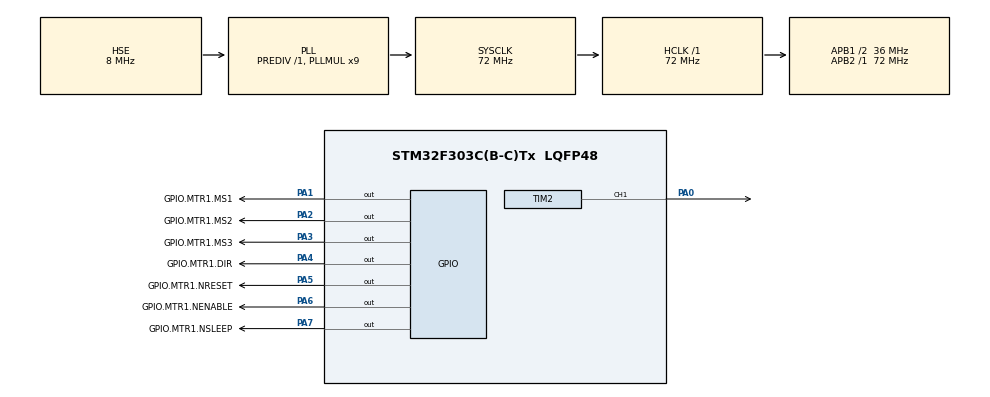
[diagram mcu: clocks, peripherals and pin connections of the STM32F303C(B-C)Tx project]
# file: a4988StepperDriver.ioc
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FREERTOS.Tasks01=defaultTask,24,128,StartDefaultTask,Default,NULL,Dynamic,NULL,NULL
FREERTOS.configUSE_NEWLIB_REENTRANT=1
Mcu.Family=STM32F3
Mcu.Name=STM32F303C(B-C)Tx
Mcu.Package=LQFP48
NVIC.PriorityGroup=NVIC_PRIORITYGROUP_4
NVIC.TIM6_DAC_IRQn=true\:15\:0\:false\:false\:true\:false\:false\:true\:true
NVIC.TimeBase=TIM6_DAC_IRQn
NVIC.TimeBaseIP=TIM6
PA0.Signal=S_TIM2_CH1_ETR
PA1.GPIO_Label=GPIO.MTR1.MS1
PA1.Signal=GPIO_Output
PA13.Mode=Serial_Wire
PA13.Signal=SYS_JTMS-SWDIO
PA14.Mode=Serial_Wire
PA14.Signal=SYS_JTCK-SWCLK
PA2.GPIO_Label=GPIO.MTR1.MS2
PA2.Signal=GPIO_Output
PA3.GPIO_Label=GPIO.MTR1.MS3
PA3.Signal=GPIO_Output
PA4.GPIO_Label=GPIO.MTR1.DIR
PA4.Signal=GPIO_Output
PA5.GPIO_Label=GPIO.MTR1.NRESET
PA5.Signal=GPIO_Output
PA6.GPIO_Label=GPIO.MTR1.NENABLE
PA6.Signal=GPIO_Output
PA7.GPIO_Label=GPIO.MTR1.NSLEEP
PA7.Signal=GPIO_Output
PF0-OSC_IN.Mode=HSE-External-Oscillator
PF0-OSC_IN.Signal=RCC_OSC_IN
PF1-OSC_OUT.Mode=HSE-External-Oscillator
PF1-OSC_OUT.Signal=RCC_OSC_OUT
ProjectManager.HeapSize=0x200
ProjectManager.StackSize=0x400
ProjectManager.TargetToolchain=STM32CubeIDE
RCC.AHBFreq_Value=72000000
RCC.APB1CLKDivider=RCC_HCLK_DIV2
RCC.APB1Freq_Value=36000000
RCC.APB1TimFreq_Value=72000000
RCC.APB2Freq_Value=72000000
RCC.APB2TimFreq_Value=72000000
RCC.CortexFreq_Value=72000000
RCC.HCLKFreq_Value=72000000
RCC.HSE_VALUE=8000000
RCC.HSI_VALUE=8000000
RCC.LSE_VALUE=32768
RCC.PLLMUL=RCC_PLL_MUL9
RCC.PLLSourceVirtual=RCC_PLLSOURCE_HSE
RCC.SYSCLKFreq_VALUE=72000000
RCC.SYSCLKSourceVirtual=RCC_SYSCLKSOURCE_PLLCLK
RCC.USBFreq_Value=72000000
SH.S_TIM2_CH1_ETR.0=TIM2_CH1,PWM Generation1 CH1
TIM2.AutoReloadPreload=TIM_AUTORELOAD_PRELOAD_ENABLE
TIM2.Channel-PWM\ Generation1\ CH1=TIM_CHANNEL_1
TIM2.Period=2-1
TIM2.Prescaler=72-1
TIM2.Pulse-PWM\ Generation1\ CH1=1-1
VP_FREERTOS_VS_CMSIS_V2.Mode=CMSIS_V2
VP_SYS_VS_tim6.Mode=TIM6
board=custom

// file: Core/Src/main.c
/* USER CODE BEGIN Header */
/**
  ******************************************************************************
  * @file           : main.c
  * @brief          : Main program body
  ******************************************************************************
  * @attention
  *
  * Copyright (c) 2024 STMicroelectronics.
  * All rights reserved.
  *
  * This software is licensed under terms that can be found in the LICENSE file
  * in the root directory of this software component.
  * If no LICENSE file comes with this software, it is provided AS-IS.
  *
  ******************************************************************************
  */
/* USER CODE END Header */
#include "main.h"
#include "cmsis_os.h"

/* USER CODE BEGIN Includes */
#include "stepperDemo.h"
#include "a4988.h"

/* USER CODE END Includes */

/* Definitions for defaultTask */
osThreadId_t defaultTaskHandle;
const osThreadAttr_t defaultTask_attributes = {
  .name = "defaultTask",
  .stack_size = 128 * 4,
  .priority = (osPriority_t) osPriorityNormal,
};

void SystemClock_Config(void);
static void MX_GPIO_Init(void);
static void MX_TIM2_Init(void);
void StartDefaultTask(void *argument);

int main(void)
{

  /* MCU Configuration--------------------------------------------------------*/

  /* Reset of all peripherals, Initializes the Flash interface and the Systick. */
  HAL_Init();

  /* Configure the system clock */
  SystemClock_Config();

  /* Initialize all configured peripherals */
  MX_GPIO_Init();
  MX_TIM2_Init();

  /* Init scheduler */
  osKernelInitialize();

  /* Create the thread(s) */
  /* creation of defaultTask */
  defaultTaskHandle = osThreadNew(StartDefaultTask, NULL, &defaultTask_attributes);

  /* Start scheduler */
  osKernelStart();

  /* We should never get here as control is now taken by the scheduler */
  /* Infinite loop */
  while (1)
  {

  }
}

void SystemClock_Config(void)
{
  RCC_OscInitTypeDef RCC_OscInitStruct = {0};
  RCC_ClkInitTypeDef RCC_ClkInitStruct = {0};

  /** Initializes the RCC Oscillators according to the specified parameters
  * in the RCC_OscInitTypeDef structure.
  */
  RCC_OscInitStruct.OscillatorType = RCC_OSCILLATORTYPE_HSE;
  RCC_OscInitStruct.HSEState = RCC_HSE_ON;
  RCC_OscInitStruct.HSEPredivValue = RCC_HSE_PREDIV_DIV1;
  RCC_OscInitStruct.HSIState = RCC_HSI_ON;
  RCC_OscInitStruct.PLL.PLLState = RCC_PLL_ON;
  RCC_OscInitStruct.PLL.PLLSource = RCC_PLLSOURCE_HSE;
  RCC_OscInitStruct.PLL.PLLMUL = RCC_PLL_MUL9;
  if (HAL_RCC_OscConfig(&RCC_OscInitStruct) != HAL_OK)
  {
    Error_Handler();
  }

  /** Initializes the CPU, AHB and APB buses clocks
  */
  RCC_ClkInitStruct.ClockType = RCC_CLOCKTYPE_HCLK|RCC_CLOCKTYPE_SYSCLK
                              |RCC_CLOCKTYPE_PCLK1|RCC_CLOCKTYPE_PCLK2;
  RCC_ClkInitStruct.SYSCLKSource = RCC_SYSCLKSOURCE_PLLCLK;
  RCC_ClkInitStruct.AHBCLKDivider = RCC_SYSCLK_DIV1;
  RCC_ClkInitStruct.APB1CLKDivider = RCC_HCLK_DIV2;
  RCC_ClkInitStruct.APB2CLKDivider = RCC_HCLK_DIV1;

  if (HAL_RCC_ClockConfig(&RCC_ClkInitStruct, FLASH_LATENCY_2) != HAL_OK)
  {
    Error_Handler();
  }
}

static void MX_TIM2_Init(void)
{

  LL_TIM_InitTypeDef TIM_InitStruct = {0};
  LL_TIM_OC_InitTypeDef TIM_OC_InitStruct = {0};

  LL_GPIO_InitTypeDef GPIO_InitStruct = {0};

  /* Peripheral clock enable */
  LL_APB1_GRP1_EnableClock(LL_APB1_GRP1_PERIPH_TIM2);

  TIM_InitStruct.Prescaler = 72-1;
  TIM_InitStruct.CounterMode = LL_TIM_COUNTERMODE_UP;
  TIM_InitStruct.Autoreload = 100-1;
  TIM_InitStruct.ClockDivision = LL_TIM_CLOCKDIVISION_DIV1;
  LL_TIM_Init(TIM2, &TIM_InitStruct);
  LL_TIM_EnableARRPreload(TIM2);
  LL_TIM_OC_EnablePreload(TIM2, LL_TIM_CHANNEL_CH1);
  TIM_OC_InitStruct.OCMode = LL_TIM_OCMODE_PWM1;
  TIM_OC_InitStruct.OCState = LL_TIM_OCSTATE_DISABLE;
  TIM_OC_InitStruct.OCNState = LL_TIM_OCSTATE_DISABLE;
  TIM_OC_InitStruct.CompareValue = 50-1;
  TIM_OC_InitStruct.OCPolarity = LL_TIM_OCPOLARITY_HIGH;
  LL_TIM_OC_Init(TIM2, LL_TIM_CHANNEL_CH1, &TIM_OC_InitStruct);
  LL_TIM_OC_DisableFast(TIM2, LL_TIM_CHANNEL_CH1);
  LL_TIM_SetTriggerOutput(TIM2, LL_TIM_TRGO_RESET);
  LL_TIM_DisableMasterSlaveMode(TIM2);
  LL_AHB1_GRP1_EnableClock(LL_AHB1_GRP1_PERIPH_GPIOA);
  /**TIM2 GPIO Configuration
  PA0   ------> TIM2_CH1
  */
  GPIO_InitStruct.Pin = LL_GPIO_PIN_0;
  GPIO_InitStruct.Mode = LL_GPIO_MODE_ALTERNATE;
  GPIO_InitStruct.Speed = LL_GPIO_SPEED_FREQ_LOW;
  GPIO_InitStruct.OutputType = LL_GPIO_OUTPUT_PUSHPULL;
  GPIO_InitStruct.Pull = LL_GPIO_PULL_NO;
  GPIO_InitStruct.Alternate = LL_GPIO_AF_1;
  LL_GPIO_Init(GPIOA, &GPIO_InitStruct);

}

static void MX_GPIO_Init(void)
{
  GPIO_InitTypeDef GPIO_InitStruct = {0};

  /* GPIO Ports Clock Enable */
  __HAL_RCC_GPIOF_CLK_ENABLE();
  __HAL_RCC_GPIOA_CLK_ENABLE();

  /*Configure GPIO pin Output Level */
  HAL_GPIO_WritePin(GPIOA, GPIO_MTR1_MS1_Pin|GPIO_MTR1_MS2_Pin|GPIO_MTR1_MS3_Pin|GPIO_MTR1_DIR_Pin
                          |GPIO_MTR1_NRESET_Pin|GPIO_MTR1_NENABLE_Pin|GPIO_MTR1_NSLEEP_Pin, GPIO_PIN_RESET);

  /*Configure GPIO pins : GPIO_MTR1_MS1_Pin GPIO_MTR1_MS2_Pin GPIO_MTR1_MS3_Pin GPIO_MTR1_DIR_Pin
                           GPIO_MTR1_NRESET_Pin GPIO_MTR1_NENABLE_Pin GPIO_MTR1_NSLEEP_Pin */
  GPIO_InitStruct.Pin = GPIO_MTR1_MS1_Pin|GPIO_MTR1_MS2_Pin|GPIO_MTR1_MS3_Pin|GPIO_MTR1_DIR_Pin
                          |GPIO_MTR1_NRESET_Pin|GPIO_MTR1_NENABLE_Pin|GPIO_MTR1_NSLEEP_Pin;
  GPIO_InitStruct.Mode = GPIO_MODE_OUTPUT_PP;
  GPIO_InitStruct.Pull = GPIO_NOPULL;
  GPIO_InitStruct.Speed = GPIO_SPEED_FREQ_LOW;
  HAL_GPIO_Init(GPIOA, &GPIO_InitStruct);

}

void StartDefaultTask(void *argument)
{
  /* USER CODE BEGIN 5 */
	STP_Startup();
	STP_SetFrequency(1000);
    osDelay(1000);
	STP_SetFrequency(5000);
    osDelay(1000);
	A4988_SET_MICROSTEP_EIGHTHSTEP();
    osDelay(1000);
	A4988_SET_MICROSTEP_QUARTERSTEP();
    osDelay(1000);

    A4988_DISABLE();
    osDelay(1);

  /* Infinite loop */
  for(;;)
  {
	  //STEP

    osDelay(1);
  }
  /* USER CODE END 5 */
}

void HAL_TIM_PeriodElapsedCallback(TIM_HandleTypeDef *htim)
{
  if (htim->Instance == TIM6) {
    HAL_IncTick();
  }
}

void Error_Handler(void)
{
  __disable_irq();
  while (1)
  {
  }
}
